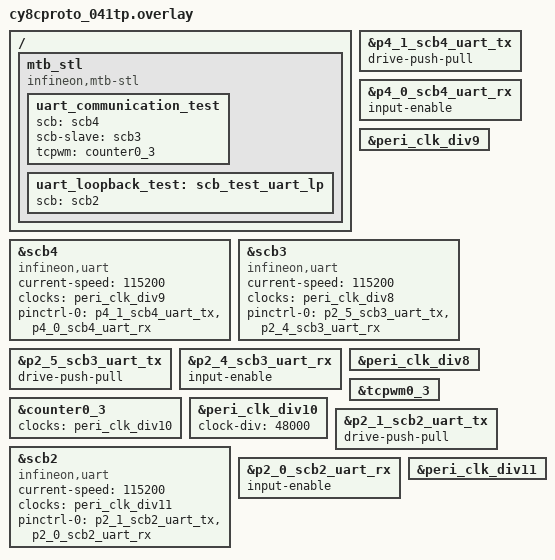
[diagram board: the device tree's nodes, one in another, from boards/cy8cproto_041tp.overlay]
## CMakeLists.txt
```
# SPDX-License-Identifier: Apache-2.0

cmake_minimum_required(VERSION 3.20.0)

find_package(Zephyr REQUIRED HINTS $ENV{ZEPHYR_BASE})
project(post-uart-test-mtb-stl)

target_sources(app PRIVATE src/main.c)
```

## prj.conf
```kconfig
# POST subsystem
CONFIG_POST=y
CONFIG_POST_VENDOR_MTB_STL=y
CONFIG_POST_SHELL=y
CONFIG_POST_HALT_ON_FAILURE=n
CONFIG_POST_RUNTIME_TESTS=y

# POST UART Tests
CONFIG_POST_MTB_STL_UART_LOOPBACK=y
CONFIG_POST_MTB_STL_COMM=y

# Shell support
CONFIG_SHELL=y

# Logging
CONFIG_LOG=y
CONFIG_POST_LOG_LEVEL=4
CONFIG_SHARED_INTERRUPTS=y
```

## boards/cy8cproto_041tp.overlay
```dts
/*
 * Copyright (c) 2025 Infineon Technologies AG,
 * or an affiliate of Infineon Technologies AG.
 *
 * SPDX-License-Identifier: Apache-2.0
 */

/*
 * Board Requirements:
 * - UART Loop Back Test (connect p2.0 -> p2.1)
 * - UART Communication Test (connect p4.0 -> p2.5 & p4.1 -> p2.4)
 */

/* Uart Communication Data transfer self test */

/* Master UART communication test */
&scb4 {
	compatible = "infineon,uart";
	status = "okay";
	current-speed = <115200>;
	clocks = <&peri_clk_div9>;
	pinctrl-0 = <&p4_1_scb4_uart_tx &p4_0_scb4_uart_rx>;
	pinctrl-names = "default";
};

&p4_1_scb4_uart_tx {
	drive-push-pull;
};

&p4_0_scb4_uart_rx {
	input-enable;
};

&peri_clk_div9 {
	status = "okay";
};

/* Slave UART communication test */
&scb3 {
	compatible = "infineon,uart";
	status = "okay";
	current-speed = <115200>;
	clocks = <&peri_clk_div8>;
	pinctrl-0 = <&p2_5_scb3_uart_tx &p2_4_scb3_uart_rx>;
	pinctrl-names = "default";
};

&p2_5_scb3_uart_tx {
	drive-push-pull;
};

&p2_4_scb3_uart_rx {
	input-enable;
};

&peri_clk_div8 {
	status = "okay";
};

/* Timer UART communication test*/
&tcpwm0_3 {
	status = "okay";
};

&counter0_3 {
	status = "okay";
	clocks = <&peri_clk_div10>;
};

&peri_clk_div10 {
	status = "okay";
	clock-div = <48000>;
};

/* UART Loop Back self test */
&scb2 {
	compatible = "infineon,uart";
	status = "okay";
	current-speed = <115200>;
	clocks = <&peri_clk_div11>;
	pinctrl-0 = <&p2_1_scb2_uart_tx &p2_0_scb2_uart_rx>;
	pinctrl-names = "default";
};

&p2_1_scb2_uart_tx {
	drive-push-pull;
};

&p2_0_scb2_uart_rx {
	input-enable;
};

&peri_clk_div11 {
	status = "okay";
};

/ {
	mtb_stl: mtb_stl {
		compatible = "infineon,mtb-stl";
		status = "okay";

		uart_communication_test: uart_communication_test {
			scb = <&scb4>;
			scb-slave = <&scb3>;
			tcpwm = <&counter0_3>;
		};

		uart_loopback_test: scb_test_uart_lp {
			scb = <&scb2>;
		};
	};
};
```

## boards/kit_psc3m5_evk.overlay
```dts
/*
 * SPDX-FileCopyrightText: Copyright (c) 2026 Infineon Technologies AG,
 * SPDX-FileCopyrightText: or an affiliate of Infineon Technologies AG. All rights reserved.
 *
 * SPDX-License-Identifier: Apache-2.0
 */

/*
 * Board Requirements (all connections on the J5 expansion header):
 * - UART Loop Back Test:     connect J5.29 (P3.3, TX) -> J5.31 (P3.2, RX)
 * - UART Communication Test: connect J5.14 (P7.1, master TX) -> J5.13 (P8.1, slave RX)
 *                            connect J5.17 (P8.3, slave TX)  -> J5.20 (P7.2, master RX)
 *
 * scb1 is the SWD debug port and scb3 is the console UART.
 */

#include <zephyr/dt-bindings/gpio/gpio.h>

/* UART Communication data transfer self test */

/* Master UART communication test */
&scb2 {
	compatible = "infineon,uart";
	status = "okay";
	current-speed = <115200>;
	clocks = <&peri0_group4_16bit_0>;
	pinctrl-0 = <&p7_1_scb2_uart_tx &p7_2_scb2_uart_rx>;
	pinctrl-names = "default";
};

&p7_1_scb2_uart_tx {
	drive-push-pull;
};

&p7_2_scb2_uart_rx {
	input-enable;
};

&peri0_group4_16bit_0 {
	status = "okay";
	clock-div = <86>;
};

/* Slave UART communication test */
&scb5 {
	compatible = "infineon,uart";
	status = "okay";
	current-speed = <115200>;
	clocks = <&peri0_group6_16_5bit_0>;
	pinctrl-0 = <&p8_3_scb5_uart_tx &p8_1_scb5_uart_rx>;
	pinctrl-names = "default";
};

&p8_3_scb5_uart_tx {
	drive-push-pull;
};

&p8_1_scb5_uart_rx {
	input-enable;
};

&peri0_group6_16_5bit_0 {
	status = "okay";
	clock-div = <86>;
};

/* Timer UART communication test */
&tcpwm0_3 {
	status = "okay";
};

&counter0_3 {
	status = "okay";
	clocks = <&peri0_group5_16bit_0>;
};

&peri0_group5_16bit_0 {
	status = "okay";
	clock-div = <48000>;
};

/* UART Loop Back self test */
&scb4 {
	compatible = "infineon,uart";
	status = "okay";
	current-speed = <115200>;
	clocks = <&peri0_group4_8bit_1>;
	pinctrl-0 = <&p3_3_scb4_uart_tx &p3_2_scb4_uart_rx>;
	pinctrl-names = "default";
};

&p3_3_scb4_uart_tx {
	drive-push-pull;
};

&p3_2_scb4_uart_rx {
	input-enable;
};

&peri0_group4_8bit_1 {
	status = "okay";
	clock-div = <86>;
};

/ {
	mtb_stl: mtb_stl {
		compatible = "infineon,mtb-stl";
		status = "okay";

		uart_communication_test: uart_communication_test {
			scb = <&scb2>;
			scb-slave = <&scb5>;
			tcpwm = <&counter0_3>;
		};

		uart_loopback_test: scb_test_uart_lp {
			scb = <&scb4>;
		};
	};
};
```

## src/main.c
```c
/*
 * Copyright (c) 2026 Aerlync Labs Inc.
 * SPDX-License-Identifier: Apache-2.0
 */

#include <zephyr/kernel.h>
#include <zephyr/post/post.h>
#include <zephyr/shell/shell.h>
#include <zephyr/logging/log.h>

LOG_MODULE_REGISTER(post_uart_sample, LOG_LEVEL_INF);

int main(void)
{
	uint32_t passed;
	uint32_t failed;
	uint32_t skipped;

	printk("\n");
	printk("====================================\n");
	printk("Starting UART POST sample application\n");
	printk("====================================\n");
	printk("\n");

	LOG_INF("POST subsystem initialized");
	LOG_INF("MTB-STL tests registered during boot");

	post_get_summary(&passed, &failed, &skipped);
	printk("POST summary: %u passed, %u failed, %u skipped\n", passed, failed, skipped);

	printk("Available shell commands:\n");
	printk("  post list   - List all registered POST tests\n");
	printk("  post run    - Run runtime POST tests\n");
	printk("  post status - Show POST test results\n");
	printk("\n");

	/* Application main loop */
	while (1) {
		k_sleep(K_SECONDS(5));
		LOG_DBG("Application running...");
	}

	return 0;
}
```
